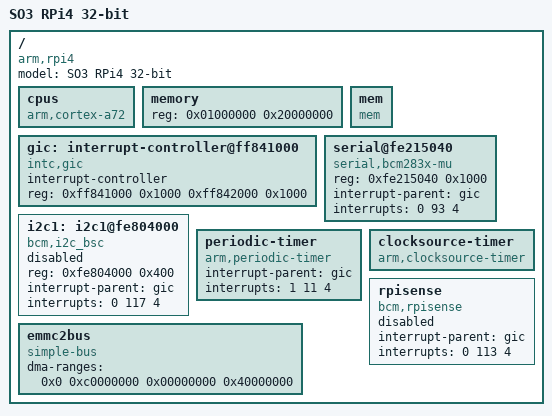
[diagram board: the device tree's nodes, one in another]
/*
 * Copyright (C) 2014-2026 REDS Institute, HEIG-VD, Yverdon
 *
 * This program is free software; you can redistribute it and/or modify
 * it under the terms of the GNU General Public License version 2 as
 * published by the Free Software Foundation.
 *
 * This program is distributed in the hope that it will be useful,
 * but WITHOUT ANY WARRANTY; without even the implied warranty of
 * MERCHANTABILITY or FITNESS FOR A PARTICULAR PURPOSE.  See the
 * GNU General Public License for more details.
 *
 * You should have received a copy of the GNU General Public License
 * along with this program; if not, write to the Free Software
 * Foundation, Inc., 51 Franklin St, Fifth Floor, Boston, MA  02110-1301  USA
 *
 */

/dts-v1/;

/ {
	model = "SO3 RPi4 32-bit";
	compatible = "arm,rpi4";

	/*
	 * Single address/size cell, unlike rpi4_64.dts: this is the 32-bit
	 * platform, so every reg below carries one address cell instead of two.
	 */
	#address-cells = <1>;
	#size-cells = <1>;

	cpus {
		device_type = "cpu";
		compatible = "arm,cortex-a72";
	};

	memory {
		device_type = "memory";
		reg = <0x01000000 0x20000000>; /* 512 MB; base = ITS load 0x01008000 - 0x8000 text offset */
	};

	mem {
		compatible = "mem";
		status = "ok";
	};

	/* GIC interrupt controller */
	gic:interrupt-controller@ff841000 {
		compatible = "intc,gic";
		interrupt-controller;
		#interrupt-cells = <3>;

		reg = <0xff841000 0x1000
		       0xff842000 0x1000>;
		status = "ok";
	};

	/* RPi4 miniuart NS16550 console */
	serial@fe215040 {
		compatible = "serial,bcm283x-mu";
		reg = <0xfe215040 0x1000>;
		interrupt-parent = <&gic>;

		/*
		 * AUX (mini UART) — SPI 93, the value Broadcom's
		 * bcm2711-rpi-4-b.dtb gives for /soc/serial@7e215040.
		 */
		interrupts = <0 93 4>;
		status = "ok";
	};

	/* I2C1 controller (Broadcom Serial Controller BSC1) */
	i2c1:i2c1@fe804000 {
		compatible = "bcm,i2c_bsc";
		reg = <0xfe804000 0x400>;
		status = "disabled";
		interrupt-parent = <&gic>;

		/* IRQ 53 of VC which start at SPI96 -> 96 + 53 = 149 */
		interrupts = <0 117 4>;
	};

	/* Periodic timer based on ARM CP15 timer */
	periodic-timer {
		compatible = "arm,periodic-timer";
		interrupt-parent = <&gic>;

		/* IRQ 10 with VT support or 11 without */
		interrupts = <1 11 4>;
		status = "ok";
	};

	/* Clocksource free-running timer based on ARM CP15 timer */
	clocksource-timer {
		compatible = "arm,clocksource-timer";
		status = "ok";
	};

	rpisense {
		compatible = "bcm,rpisense";
		interrupt-parent = <&gic>;
		interrupts = <0 113 4>;
		status = "disabled";
	};

	/*
	 * Present only so U-Boot's RPi 4 bootm fixup can copy the
	 * firmware-corrected dma-ranges into this static DT (see u-boot
	 * boot/bootm.c, CONFIG_BCM2711). Silences the "Can't find emmc2bus in
	 * the DT stored in the ITB" warning. SO3 boots from ramfs and does not
	 * drive emmc2 itself, so the child controller node is intentionally
	 * omitted. The parent address in ranges/dma-ranges is a single cell
	 * here, matching this tree's #address-cells.
	 */
	emmc2bus {
		compatible = "simple-bus";
		#address-cells = <2>;
		#size-cells = <1>;
		ranges = <0x0 0x7e000000  0xfe000000  0x01800000>;
		dma-ranges = <0x0 0xc0000000  0x00000000  0x40000000>;
	};

};
